VERSION ""

NS_ :

BS_:

BU_: PRNDL VCU
VAL_TABLE_ IlluminationStatus 1 "Illuminated" 0 "Not Illuminated" ;
VAL_TABLE_ ShiftPositions 6 "HighLow" 5 "P" 4 "R2" 3 "R1" 2 "L1" 1 "L2" 0 "Invalid" ;

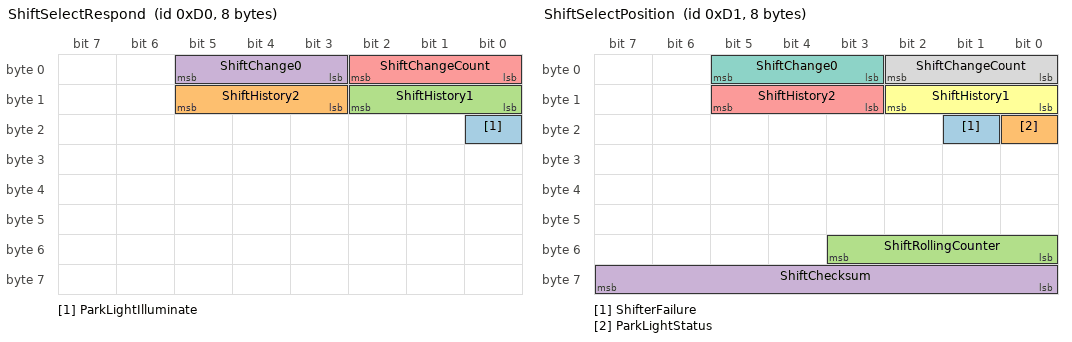
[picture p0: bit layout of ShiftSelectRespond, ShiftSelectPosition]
BO_ 208 ShiftSelectRespond: 8 Vector__XXX
 SG_ ParkLightIlluminate : 16|1@1+ (1,0) [0|0] "" Vector__XXX
 SG_ ShiftHistory2 : 11|3@1+ (1,0) [0|7] "" Vector__XXX
 SG_ ShiftHistory1 : 8|3@1+ (1,0) [0|7] "" Vector__XXX
 SG_ ShiftChange0 : 3|3@1+ (1,0) [0|7] "" Vector__XXX
 SG_ ShiftChangeCount : 0|3@1+ (1,0) [0|7] "" Vector__XXX

BO_ 209 ShiftSelectPosition: 8 Vector__XXX
 SG_ ShifterFailure : 17|1@1+ (1,0) [0|0] "" Vector__XXX
 SG_ ParkLightStatus : 16|1@1+ (1,0) [0|0] "" Vector__XXX
 SG_ ShiftRollingCounter : 48|4@1+ (1,0) [0|15] "" Vector__XXX
 SG_ ShiftChecksum : 56|8@1+ (1,0) [0|255] "" Vector__XXX
 SG_ ShiftHistory2 : 11|3@1+ (1,0) [0|7] "" Vector__XXX
 SG_ ShiftHistory1 : 8|3@1+ (1,0) [0|7] "" Vector__XXX
 SG_ ShiftChange0 : 3|3@1+ (1,0) [0|7] "" Vector__XXX
 SG_ ShiftChangeCount : 0|3@1+ (1,0) [0|7] "" Vector__XXX

CM_ SG_ 208 ParkLightIlluminate "Status of Park Light illumination state";
CM_ SG_ 208 ShiftHistory2 "Third most recent input request by driver. This should be the last value of Change0 when a new input is made.";
CM_ SG_ 208 ShiftHistory1 "Second most recent input request by driver. This should be the last value of Change0 when a new input is made.";
CM_ SG_ 208 ShiftChange0 "Most recent input request by driver";
CM_ SG_ 208 ShiftChangeCount "Incrementing change counter";
CM_ SG_ 209 ShifterFailure "Indicates shifter failure";
CM_ SG_ 209 ParkLightStatus "Status of Park Light illumination state";
CM_ SG_ 209 ShiftRollingCounter "Rolling counter";
CM_ SG_ 209 ShiftChecksum "Checksum of message
";
CM_ SG_ 209 ShiftHistory2 "Third most recent input request by driver. This should be the last value of Change0 when a new input is made.";
CM_ SG_ 209 ShiftHistory1 "Second most recent input request by driver. This should be the last value of Change0 when a new input is made.";
CM_ SG_ 209 ShiftChange0 "Most recent input request by driver";
CM_ SG_ 209 ShiftChangeCount "Incrementing change counter";
BA_DEF_  "DBName" STRING ;
BA_DEF_ SG_  "SigType" ENUM  "Default","Range","RangeSigned","ASCII","Discrete","Control","ReferencePGN","DTC","StringDelimiter","StringLength","StringLengthControl","MessageCounter","MessageChecksum";
BA_DEF_ SG_  "GenSigSendType" ENUM  "Cyclic","OnWrite","OnWriteWithRepetition","OnChange","OnChangeWithRepetition","IfActive","IfActiveWithRepetition","NoSigSendType";
BA_DEF_ SG_  "GenSigILSupport" ENUM  "No","Yes";
BA_DEF_ SG_  "GenSigEVName" STRING ;
BA_DEF_ BO_  "GenMsgILSupport" ENUM  "No","Yes";
BA_DEF_ BO_  "GenMsgRequestable" INT 0 1;
BA_DEF_ BO_  "GenMsgSendType" ENUM  "cyclic","NotUsed","NotUsed","NotUsed","NotUsed","NotUsed","NotUsed","IfActive","noMsgSendType";
BA_DEF_ BO_  "VFrameFormat" ENUM  "StandardCAN","ExtendedCAN","reserved","J1939PG";
BA_DEF_ BO_  "GenMsgCycleTime" INT 0 3600000;
BA_DEF_ BU_  "NmStationAddress" INT 0 255;
BA_DEF_  "SAE_J1939_DA_SpecVersion" STRING ;
BA_DEF_  "SAE_J1939_81_SpecVersion" STRING ;
BA_DEF_  "DatabaseVersion" STRING ;
BA_DEF_  "BusType" STRING ;
BA_DEF_  "ProtocolType" STRING ;
BA_DEF_  "SAE_J1939_75_SpecVersion" STRING ;
BA_DEF_  "SAE_J1939_21_SpecVersion" STRING ;
BA_DEF_  "SAE_J1939_73_SpecVersion" STRING ;
BA_DEF_  "SAE_J1939_71_SpecVersion" STRING ;
BA_DEF_DEF_  "DBName" "";
BA_DEF_DEF_  "SigType" "Default";
BA_DEF_DEF_  "GenSigSendType" "NoSigSendType";
BA_DEF_DEF_  "GenSigILSupport" "Yes";
BA_DEF_DEF_  "GenSigEVName" "Env@Nodename_@Signame";
BA_DEF_DEF_  "GenMsgILSupport" "Yes";
BA_DEF_DEF_  "GenMsgRequestable" 1;
BA_DEF_DEF_  "GenMsgSendType" "noMsgSendType";
BA_DEF_DEF_  "VFrameFormat" "J1939PG";
BA_DEF_DEF_  "GenMsgCycleTime" 0;
BA_DEF_DEF_  "NmStationAddress" 254;
BA_DEF_DEF_  "SAE_J1939_DA_SpecVersion" "";
BA_DEF_DEF_  "SAE_J1939_81_SpecVersion" "";
BA_DEF_DEF_  "DatabaseVersion" "";
BA_DEF_DEF_  "BusType" "";
BA_DEF_DEF_  "ProtocolType" "";
BA_DEF_DEF_  "SAE_J1939_75_SpecVersion" "";
BA_DEF_DEF_  "SAE_J1939_21_SpecVersion" "";
BA_DEF_DEF_  "SAE_J1939_73_SpecVersion" "";
BA_DEF_DEF_  "SAE_J1939_71_SpecVersion" "";
BA_ "SAE_J1939_71_SpecVersion" "2016-10";
BA_ "SAE_J1939_73_SpecVersion" "2013-07";
BA_ "SAE_J1939_21_SpecVersion" "2016-03";
BA_ "SAE_J1939_75_SpecVersion" "2015-11";
BA_ "ProtocolType" "J1939";
BA_ "BusType" "CAN";
BA_ "DatabaseVersion" "10.0";
BA_ "SAE_J1939_81_SpecVersion" "2017-03";
BA_ "SAE_J1939_DA_SpecVersion" "2018-02";
BA_ "DBName" "J1939";
BA_ "NmStationAddress" BU_ VCU 90;
BA_ "VFrameFormat" BO_ 208 0;
BA_ "GenMsgCycleTime" BO_ 208 50;
BA_ "VFrameFormat" BO_ 209 0;
BA_ "GenMsgCycleTime" BO_ 209 20;
VAL_ 208 ParkLightIlluminate 1 "Illuminated" 0 "Not Illuminated" ;
VAL_ 208 ShiftHistory2 6 "HighLow" 5 "P" 4 "R2" 3 "R1" 2 "L1" 1 "L2" 0 "Invalid" ;
VAL_ 208 ShiftHistory1 6 "HighLow" 5 "P" 4 "R2" 3 "R1" 2 "L1" 1 "L2" 0 "Invalid" ;
VAL_ 208 ShiftChange0 6 "HighLow" 5 "P" 4 "R2" 3 "R1" 2 "L1" 1 "L2" 0 "Invalid" ;
VAL_ 209 ParkLightStatus 1 "Illuminated" 0 "Not Illuminated" ;
VAL_ 209 ShiftHistory2 6 "HighLow" 5 "P" 4 "R2" 3 "R1" 2 "L1" 1 "L2" 0 "Invalid" ;
VAL_ 209 ShiftHistory1 6 "HighLow" 5 "P" 4 "R2" 3 "R1" 2 "L1" 1 "L2" 0 "Invalid" ;
VAL_ 209 ShiftChange0 6 "HighLow" 5 "P" 4 "R2" 3 "R1" 2 "L1" 1 "L2" 0 "Invalid" ;
